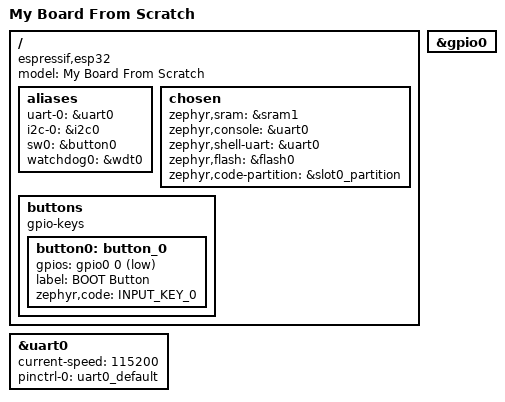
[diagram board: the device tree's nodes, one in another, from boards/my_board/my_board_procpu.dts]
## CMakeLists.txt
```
cmake_minimum_required(VERSION 3.20.0)

list(APPEND BOARD_ROOT ${CMAKE_CURRENT_SOURCE_DIR})
list(APPEND DTS_BINDINGS ${CMAKE_CURRENT_SOURCE_DIR}/dts/bindings)
find_package(Zephyr REQUIRED HINTS $ENV{ZEPHYR_BASE})
project(my_zephyr_app)

target_include_directories(app PRIVATE drivers/led_driver)
target_sources(app PRIVATE src/main.cpp)
add_subdirectory(drivers/led_driver)
```

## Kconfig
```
config APP_HEARBEAT_PERIOD_MS
  int "Hearbeat perios ms"
  range 100 2000
  default 500

source "Kconfig.zephyr"
rsource "drivers/led_driver/Kconfig"
```

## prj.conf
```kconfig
CONFIG_GPIO=y
CONFIG_LOG=y
CONFIG_APP_HEARBEAT_PERIOD_MS=500
CONFIG_LED_DRIVER=y

CONFIG_SHELL=y
CONFIG_DEVICE_SHELL=y
```

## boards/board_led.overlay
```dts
/{
    board_led = &app_led;
};
```

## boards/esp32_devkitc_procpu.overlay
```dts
/ {
    led{
        compatible = "gpio-leds";
        app_led: led0{
            gpios = <&gpio0 2 GPIO_ACTIVE_LOW>;
        };
    };
};
```

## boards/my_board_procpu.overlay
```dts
/ {
    led_driver0: led_driver{
        compatible = "led_driver";
        calibration = <50>;
        sleep-ms = <200>;
        gpios = <&gpio0 2 0>;
        status = "okay";
    };
};
```

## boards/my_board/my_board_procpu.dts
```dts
/dts-v1/;

#include <espressif/esp32/esp32_wrover_e_n4r8.dtsi>
#include <zephyr/dt-bindings/input/input-event-codes.h>
#include <espressif/partitions_0x1000_amp.dtsi>
#include "esp32_devkitc-pinctrl.dtsi"

/ {
	model = "My Board From Scratch";
	compatible = "espressif,esp32";

    aliases {
		uart-0 = &uart0;
		i2c-0 = &i2c0;
		sw0 = &button0;
		watchdog0 = &wdt0;
	};

    chosen {
		zephyr,sram = &sram1;
		zephyr,console = &uart0;
		zephyr,shell-uart = &uart0;
		zephyr,flash = &flash0;
		zephyr,code-partition = &slot0_partition;
	};

    buttons {
		compatible = "gpio-keys";

		button0: button_0 {
			gpios = <&gpio0 0 (GPIO_PULL_UP | GPIO_ACTIVE_LOW)>;
			label = "BOOT Button";
			zephyr,code = <INPUT_KEY_0>;
		};
	};
};

&uart0 {
	status = "okay";
	current-speed = <115200>;
	pinctrl-0 = <&uart0_default>;
	pinctrl-names = "default";
};

&gpio0 {
	status = "okay";
};
```

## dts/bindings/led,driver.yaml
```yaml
description: custom driver for lesson 6 assignment
compatible: "led_driver"      # this value should match the name of the file (without the .yaml extension) and the compatible string used in the device tree
include: base.yaml
properties:
  calibration:
    type: int
    required: true
    description: Calibration value for the sensor
  sleep-ms:
    type: int
    required: true
    description: Duration in milliseconds for k_msleep calls in the driver
  gpios:
    type: phandle-array
    required: true
    description: GPIO spec for the LED to control
```

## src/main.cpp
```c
#include <zephyr/kernel.h>
#include <zephyr/drivers/sensor.h>
#include <zephyr/shell/shell.h>
#include "led_driver.h"

#define LED_DEV_NODE DT_INST(0, led_driver)

static int cmd_sensor_fetch(const struct shell *sh, size_t argc, char **argv)
{
    const struct device *dev = DEVICE_DT_GET(LED_DEV_NODE);
    if (!device_is_ready(dev)) {
        shell_error(sh, "Device not ready");
        return -ENODEV;
    }

    int ret = sensor_sample_fetch(dev);
    if (ret < 0) {
        shell_error(sh, "Failed to fetch sample: %d", ret);
        return ret;
    }

    return 0;
}

static int cmd_sensor_read(const struct shell *sh, size_t argc, char **argv)
{
    const struct device *dev = DEVICE_DT_GET(LED_DEV_NODE);
    if (!device_is_ready(dev)) {
        shell_error(sh, "Device not ready");
        return -ENODEV;
    }

    struct sensor_value val;
    int ret = sensor_channel_get(dev, SENSOR_CHAN_VOLTAGE, &val);
    if (ret < 0) {
        shell_error(sh, "Failed to read sensor: %d", ret);
        return ret;
    }

    return 0;
}

static int cmd_sensor_info(const struct shell *sh, size_t argc, char **argv)
{
    const struct device *dev = DEVICE_DT_GET(LED_DEV_NODE);

    shell_print(sh, "Device name: %s", dev->name);
    shell_print(sh, "Device ready: %s", device_is_ready(dev) ? "yes" : "no");
    shell_print(sh, "Sleep ms: %u", led_drv_get_sleep_ms(dev));
    return 0;
}

static int cmd_sensor_set(const struct shell *sh, size_t argc, char **argv)
{
    const struct device *dev = DEVICE_DT_GET(LED_DEV_NODE);
    if (!device_is_ready(dev)) {
        shell_error(sh, "Device not ready");
        return -ENODEV;
    }

    if (argc < 2) {
        shell_error(sh, "Missing argument. Usage: sensor set <0-10000>");
        return -EINVAL;
    }

    int err;
    unsigned long raw = shell_strtoul(argv[1], 0, &err);
    if (err < 0) {
        shell_error(sh, "Invalid argument: %s", argv[1]);
        return -EINVAL;
    }

    if (raw > 10000) {
        shell_error(sh, "Value out of range (0-10000): %lu", raw);
        return -EINVAL;
    }

    led_drv_set_blink_delay(dev, (uint32_t)raw);
    shell_print(sh, "Blink delay set to %lu ms", raw);
    return 0;
}

SHELL_STATIC_SUBCMD_SET_CREATE(sub_sensor,
    SHELL_CMD(fetch, NULL, "Call sensor_sample_fetch()", cmd_sensor_fetch),
    SHELL_CMD(set,   NULL, "Set blink delay. Usage: sensor set <0-10000>", cmd_sensor_set),
    SHELL_CMD(read,  NULL, "Call sensor_channel_get() and print result", cmd_sensor_read),
    SHELL_CMD(info,  NULL, "Print device name and ready state", cmd_sensor_info),
    SHELL_SUBCMD_SET_END
);

SHELL_CMD_REGISTER(sensor, &sub_sensor, "Sensor driver shell commands", NULL);

int main(void)
{
    printk("LED driver shell example started\n");
    printk("Type 'sensor fetch'/'sensor read'/'sensor info' in the shell\n");

    while (true) {
        k_msleep(1000);
    }
    return 0;
}
```
